# STM32N645 register map
File version: 1.0
CPU: CM55 r0p1, little endian, no MPU, FPU, vendor SysTick, 8 interrupt priority bits
Registers are 32-bit, read-write, reset 0x0 unless marked. A register's access mark holds for its fields unless they carry their own. Offsets are from the block's base; [hi:lo] are bit positions; {n}, {i} and the like mark numbered series.

## DBGMCU — Microcontroller debug unit
Base 0x44001000
Same registers: DBGMCU_S 0x54001000
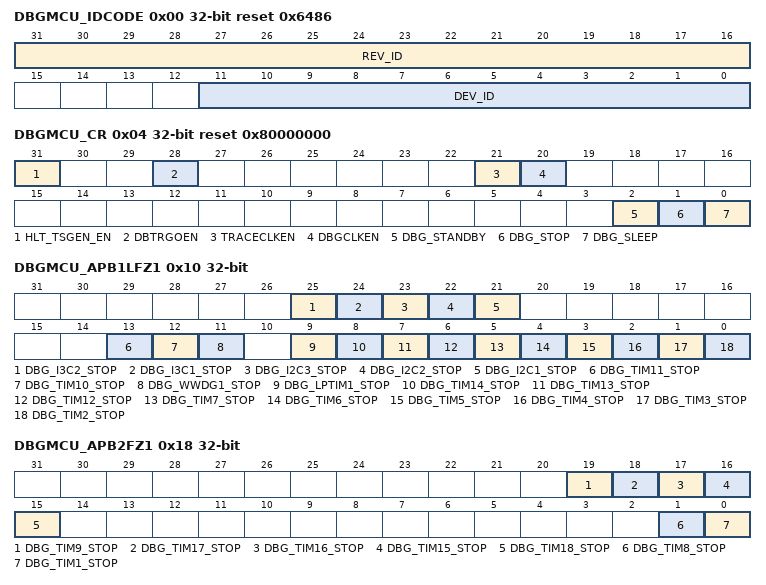
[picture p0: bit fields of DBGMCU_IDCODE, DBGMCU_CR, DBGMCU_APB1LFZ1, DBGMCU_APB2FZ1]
0x00 DBGMCU_IDCODE ro reset 0x6486 (reset mask 0xFFFF) — DBGMCU identity code register
  [31:16] REV_ID — Revision
  [11:0] DEV_ID — Device ID
    0x486=STM32N6xx
0x04 DBGMCU_CR reset 0x80000000 — DBGMCU configuration register
  [31] HLT_TSGEN_EN — TSGEN halt enable
    1=TSGEN stops counting when processor is in halt; 0=TSGEN keeps on counting when processor is in halt
  [28] DBTRGOEN — DBTRGIO connection control
    0=DBTRGIO connected to DBTRGIN; 1=DBTRGIO connected to DBTRGOUT
  [21] TRACECLKEN — TPIU export clock enable through software
    0=TPIU clock is off; 1=TPIU clock is on
  [20] DBGCLKEN — Debug clock enable through software
    0=Debug clock is off; 1=Debug clock is on
  [2] DBG_STANDBY — Allow debug in Standby mode
    0=Normal operation. All clocks are disabled and the V less than sub>DD less than /sub> domain powered down automatically in Standby mode.; 1=Automatic clock stop/power down disabled. All active clocks and oscillators continue to run during Standby mode, and the V less than sub>DD less than /sub> domain supply is maintained, allowing full debug capability.
  [1] DBG_STOP — Allow debug in Stop mode
    0=Normal operation. All clocks are disabled automatically in Stop mode; 1=Automatic clock stop disabled. All active clocks and oscillators continue to run during Stop mode, allowing full debug capability.
  [0] DBG_SLEEP — Allow debug in Sleep mode
    0=Normal operation. Peripheral clock are stopped automatically in Sleep mode; 1=Automatic clock stop disabled. Peripheral clock continues to run, allowing full debug capability.
0x10 DBGMCU_APB1LFZ1 — DBGMCU APB1L peripheral freeze register
  [25] DBG_I3C2_STOP — I3C2 SMBUS timeout stop in debug
    0=Normal operation. I3C2 SMBUS timeout continues to operate while Cortex-M55 is in debug mode.; 1=Stop in debug. I3C2 SMBUS timeout is frozen while Cortex-M55 is in debug mode.
  [24] DBG_I3C1_STOP — I3C1 SMBUS timeout stop in debug
    0=Normal operation. I3C1 SMBUS timeout continues to operate while Cortex-M55 is in debug mode.; 1=Stop in debug. I3C1 SMBUS timeout is frozen while Cortex-M55 is in debug mode.
  [23] DBG_I2C3_STOP — I2C3 SMBUS timeout stop in debug
    0=Normal operation. I2C3 SMBUS timeout continues to operate while Cortex-M55 is in debug mode.; 1=Stop in debug. I2C3 SMBUS timeout is frozen while Cortex-M55 is in debug mode.
  [22] DBG_I2C2_STOP — I2C2 SMBUS timeout stop in debug
    0=Normal operation. I2C2 SMBUS timeout continues to operate while Cortex-M55 is in debug mode.; 1=Stop in debug. I2C2 SMBUS timeout is frozen while Cortex-M55 is in debug mode.
  [21] DBG_I2C1_STOP — I2C1 SMBUS timeout stop in debug
    0=Normal operation. I2C1 SMBUS timeout continues to operate while Cortex-M55 is in debug mode.; 1=Stop in debug. I2C1 SMBUS timeout is frozen while Cortex-M55 is in debug mode.
  [13] DBG_TIM11_STOP — TIM11 stop in debug
    0=Normal operation. TIM11 continues to operate while Cortex-M55 is in debug mode.; 1=Stop in debug. TIM11 is frozen while Cortex-M55 is in debug mode.
  [12] DBG_TIM10_STOP — TIM10 stop in debug
    0=Normal operation. TIM10 continues to operate while Cortex-M55 is in debug mode.; 1=Stop in debug. TIM10 is frozen while Cortex-M55 is in debug mode.
  [11] DBG_WWDG1_STOP — WWDG1 stop in debug
    0=Normal operation. WWDG1 continues to operate while Cortex-M55 is in debug mode.; 1=Stop in debug. WWDG1 is frozen while Cortex-M55 is in debug mode.
  [9] DBG_LPTIM1_STOP — LPTIM1 stop in debug
    0=Normal operation. LPTIM1 continues to operate while Cortex-M55 is in debug mode.; 1=Stop in debug. LPTIM1 is frozen while Cortex-M55 is in debug mode.
  [8] DBG_TIM14_STOP — TIM14 stop in debug
    0=Normal operation. TIM14 continues to operate while Cortex-M55 is in debug mode.; 1=Stop in debug. TIM14 is frozen while Cortex-M55 is in debug mode.
  [7] DBG_TIM13_STOP — TIM13 stop in debug
    0=Normal operation. TIM13 continues to operate while Cortex-M55 is in debug mode.; 1=Stop in debug. TIM13 is frozen while Cortex-M55 is in debug mode.
  [6] DBG_TIM12_STOP — TIM12 stop in debug
    0=Normal operation. TIM12 continues to operate while Cortex-M55 is in debug mode.; 1=Stop in debug. TIM12 is frozen while Cortex-M55 is in debug mode.
  [5] DBG_TIM7_STOP — TIM7 stop in debug
    0=Normal operation. TIM7 continues to operate while Cortex-M55 is in debug mode.; 1=Stop in debug. TIM7 is frozen while Cortex-M55 is in debug mode.
  [4] DBG_TIM6_STOP — TIM6 stop in debug
    0=Normal operation. TIM6 continues to operate while Cortex-M55 is in debug mode.; 1=Stop in debug. TIM6 is frozen while Cortex-M55 is in debug mode.
  [3] DBG_TIM5_STOP — TIM5 stop in debug
    0=Normal operation. TIM5 continues to operate while Cortex-M55 is in debug mod.e; 1=Stop in debug. TIM5 is frozen while Cortex-M55 is in debug mode.
  [2] DBG_TIM4_STOP — TIM4 stop in debug
    0=Normal operation. TIM4 continues to operate while Cortex-M55 is in debug mode.; 1=Stop in debug. TIM4 is frozen while Cortex-M55 is in debug mode.
  [1] DBG_TIM3_STOP — TIM3 stop in debug
    0=Normal operation. TIM3 continues to operate while Cortex-M55 is in debug mode.; 1=Stop in debug. TIM3 is frozen while Cortex-M55 is in debug mode.
  [0] DBG_TIM2_STOP — TIM2 stop in debug
    0=Normal operation. TIM2 continues to operate while Cortex-M55 is in debug mode.; 1=Stop in debug. TIM2 is frozen while Cortex-M55 is in debug mode.
0x14 DBGMCU_APB1HFZ1 — DBGMCU APB1H peripheral freeze register
  [8] DBG_FDCAN_STOP — FDCAN stop in debug
    0=Normal operation. FDCAN continues to operate while Cortex-M55 is in debug mode.; 1=Stop in debug. FDCAN is frozen while Cortex-M55 is in debug mode.
0x18 DBGMCU_APB2FZ1 — DBGMCU APB2 peripheral freeze register
  [19] DBG_TIM9_STOP — TIM9 stop in debug
    0=Normal operation. TIM9 continues to operate while Cortex-M55 is in debug mode.; 1=Stop in debug. TIM9 is frozen while Cortex-M55 is in debug mode.
  [18] DBG_TIM17_STOP — TIM17 stop in debug
    0=Normal operation. TIM17 continues to operate while Cortex-M55 is in debug mode.; 1=Stop in debug. TIM17 is frozen while Cortex-M55 is in debug mode.
  [17] DBG_TIM16_STOP — TIM16 stop in debug
    0=Normal operation. TIM16 continues to operate while Cortex-M55 is in debug mode.; 1=Stop in debug. TIM16 is frozen while Cortex-M55 is in debug mode.
  [16] DBG_TIM15_STOP — TIM15 stop in debug
    0=Normal operation. TIM15 continues to operate while Cortex-M55 is in debug mode.; 1=Stop in debug. TIM15 is frozen while Cortex-M55 is in debug mode.
  [15] DBG_TIM18_STOP — TIM18 stop in debug
    0=Normal operation. TIM18 continues to operate while Cortex-M55 is in debug mode.; 1=Stop in debug. TIM18 is frozen while Cortex-M55 is in debug mode.
  [1] DBG_TIM8_STOP — TIM8 stop in debug
    0=Normal operation. TIM8 continues to operate while Cortex-M55 is in debug mode.; 1=Stop in debug. TIM8 is frozen while Cortex-M55 is in debug mode.
  [0] DBG_TIM1_STOP — TIM1 stop in debug
    0=Normal operation. TIM1 continues to operate while Cortex-M55 is in debug mode.; 1=Stop in debug. TIM1 is frozen while Cortex-M55 is in debug mode.
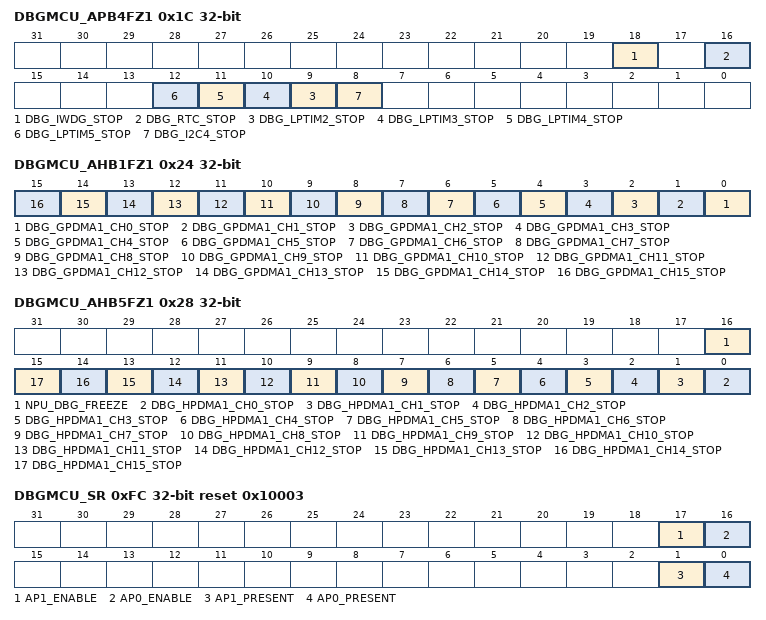
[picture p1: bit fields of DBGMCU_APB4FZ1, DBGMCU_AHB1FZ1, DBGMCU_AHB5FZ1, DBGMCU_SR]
0x1C DBGMCU_APB4FZ1 — DBGMCU APB4 peripheral freeze register
  [18] DBG_IWDG_STOP — WWDG stop in debug
    0=Normal operation. IWDG continues to operate while Cortex-M55 is in debug mode.; 1=Stop in debug. IWDG is frozen while Cortex-M55 is in debug mode.
  [16] DBG_RTC_STOP — RTC clock is suspended in debug
    0=Normal operation. Real time clock continues to operate while Cortex-M55 is in debug mode.; 1=Stop in debug. Real time clock is suspended while Cortex-M55 is in debug mode.
  [n+7] DBG_LPTIM{n}_STOP (n=2..5) — LPTIM{n} stop in debug
    0=Normal operation. LPTIM{n} continues to operate while Cortex-M55 is in debug mode.; 1=Stop in debug. LPTIM{n} is frozen while Cortex-M55 is in debug mode.
  [8] DBG_I2C4_STOP — I2C4 stop in debug
    0=Normal operation. I2C4 continues to operate while Cortex-M55 is in debug mode.; 1=Stop in debug. I2C4 is frozen while Cortex-M55 is in debug mode.
0x20 DBGMCU_APB5FZ1 — DBGMCU APB5 peripheral freeze register
  [4] DBG_GFXTIM_STOP — GFXTIM stop in debug
    0=Normal operation. GFX timer continues counting while Cortex-M55 is in debug mode.; 1=Stop in debug. GFX timer is frozen while Cortex-M55 is in debug mode.
0x24 DBGMCU_AHB1FZ1 — DBGMCU AHB1 peripheral freeze register
  [all] fields
    0=Normal operation. GPDMA1_CHn continues to operate while Cortex-M55 is in debug mode.; 1=Stop in debug. GPDMA1_CHn is suspended while Cortex-M55 is in debug mode.
  [n] DBG_GPDMA1_CH{n}_STOP (n=0..15) — GPDMA1_CHn suspend in debug
0x28 DBGMCU_AHB5FZ1 — DBGMCU AHB5 peripheral freeze register
  [16] NPU_DBG_FREEZE — NPU stop in debug mode
    0=Normal operation. The NPU continues to operate while Cortex-M55 is in debug mode.; 1=Stop in debug. NPU is suspended while Cortex-M55 is in debug mode.
  [n] DBG_HPDMA1_CH{n}_STOP (n=0..15) — HPDMA3_CHn suspend in debug
    0=Normal operation. HPDMA3_CHn continues to operate while Cortex-M55 is in debug mode.; 1=Stop in debug. HPDMA3_CHn is suspended while Cortex-M55 is in debug mode.
0xFC DBGMCU_SR ro reset 0x10003 — DBGMCU status register
  [17] AP1_ENABLE — Access point 1 enable
    0=AP disabled (debug access locked); 1=AP enabled (debug access open)
  [16] AP0_ENABLE — Access point 0 enable
    1=Always enable
  [1] AP1_PRESENT — Access point 1 presence
    1=AP present
  [0] AP0_PRESENT — Access point 0 presence
    1=AP present
0x100 DBGMCU_DBG_AUTH_HOST — DBGMCU host authentication register
  [31:0] MESSAGE — Mailbox between debugger and processor
0x104 DBGMCU_DBG_AUTH_DEV — DBGMCU device authentication register
  [31:0] MESSAGE — Mailbox between debugger and processor
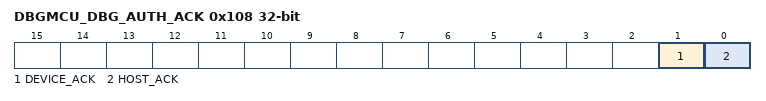
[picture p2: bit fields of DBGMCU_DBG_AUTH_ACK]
0x108 DBGMCU_DBG_AUTH_ACK ro — DBGMCU message read acknowledge authentication register
  [1] DEVICE_ACK — Access status to DBG_AUTH_DEV register
    1=Processor has written DBG_AUTH_DEV; 0=Debugger has read DBG_AUTH_DEV
  [0] HOST_ACK — Access status to DBG_AUTH_HOST register
    1=Debugger has written DBG_AUTH_HOST; 0=Processor has read DBG_AUTH_HOST
